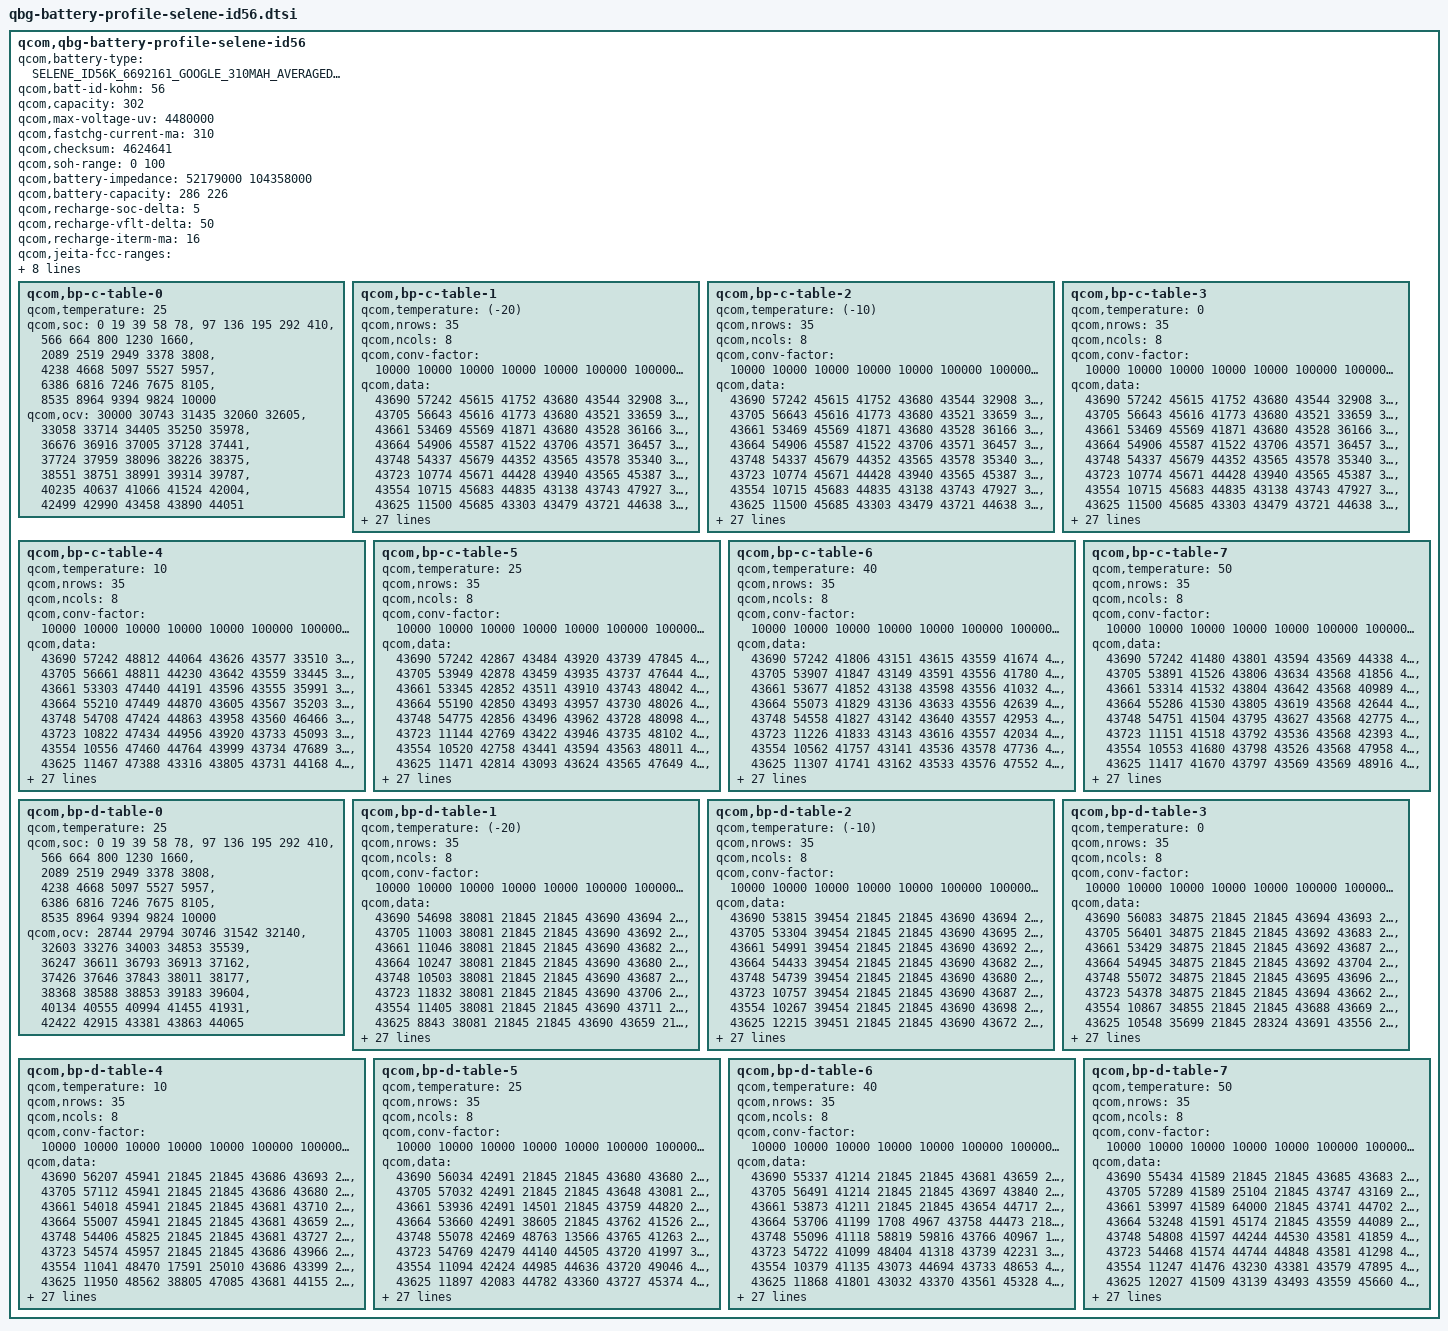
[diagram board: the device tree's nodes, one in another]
/*QBG Profiling Rev. 2.7*/

qcom,qbg-battery-profile-selene-id56 {
	qcom,battery-type = "SELENE_ID56K_6692161_GOOGLE_310MAH_AVERAGED_MASTERSLAVE_JUL3RD2023";
	qcom,batt-id-kohm = <56>;
	qcom,capacity = <302>;
	qcom,max-voltage-uv = <4480000>;
	qcom,fastchg-current-ma = <310>;
	qcom,checksum = <4624641>; /*@5, 0.005V, 4% */
	qcom,soh-range = <0 100>;
	/*Nominal_Impedance in 10nohm @ SOC 50% 25C* 0:fresh cell, 1: aged cell*/
	qcom,battery-impedance = <52179000 104358000>;
	/*Nominal_Capacity in mAh. 0: fresh cell, 1:aged cell*/ 
	qcom,battery-capacity = <286 226>;
	/*SOC delta (in percent) dropped from EOC SOC to enable recharge*/ 
	qcom,recharge-soc-delta =<5>;
	/*vfloat delta (in mV) dropped from regular vfloat in recharge*/ 
	qcom,recharge-vflt-delta =<50>;
	/*termination current (in mA) in recharge*/ 
	qcom,recharge-iterm-ma = <16>;

	qcom,jeita-fcc-ranges = <0  100 125000
				100 150 175000
				150 250 450000
				250 410 500000
				410 450 125000>;

	qcom,jeita-fv-ranges = <0   100 4480000
				100 150 4480000
				150 250 4480000
				250 410 4480000
				410 450 4480000>;

	/* COOL = 10 DegC, WARM = 41 DegC */
	qcom,jeita-soft-thresholds = <0x2b8a 0x14de>;
	/* COLD = 0 DegC, HOT = 45 DegC */
	qcom,jeita-hard-thresholds = <0x3257 0x128c>;
	/* COOL = 12 DegC, WARM = 39 DegC*/
	qcom,jeita-soft-hys-thresholds = <0x2a0b 0x161b>;
	qcom,jeita-soft-fcc-ua = <125000 125000>;
	qcom,jeita-soft-fv-uv = <4480000 4480000>;

	qcom,bp-c-table-0 {
		qcom,temperature = <25>;
		qcom,soc = <    0    19    39    58    78>,
			<   97   136   195   292   410>,
			<  566   664   800  1230  1660>,
			< 2089  2519  2949  3378  3808>,
			< 4238  4668  5097  5527  5957>,
			< 6386  6816  7246  7675  8105>,
			< 8535  8964  9394  9824 10000>;
		qcom,ocv = <30000 30743 31435 32060 32605>,
			<33058 33714 34405 35250 35978>,
			<36676 36916 37005 37128 37441>,
			<37724 37959 38096 38226 38375>,
			<38551 38751 38991 39314 39787>,
			<40235 40637 41066 41524 42004>,
			<42499 42990 43458 43890 44051>;
	};
	qcom,bp-c-table-1 {
		qcom,temperature = <(-20)>;
		qcom,nrows = <35>;
		qcom,ncols = <8>;
		qcom,conv-factor = <10000 10000 10000 10000 10000 100000 100000 10000>;
		qcom,data = <43690 57242 45615 41752 43680 43544 32908 39503>,
			<43705 56643 45616 41773 43680 43521 33659 39644>,
			<43661 53469 45569 41871 43680 43528 36166 39593>,
			<43664 54906 45587 41522 43706 43571 36457 34087>,
			<43748 54337 45679 44352 43565 43578 35340 34237>,
			<43723 10774 45671 44428 43940 43565 45387 33803>,
			<43554 10715 45683 44835 43138 43743 47927 34666>,
			<43625 11500 45685 43303 43479 43721 44638 34319>,
			<43918  9017 45691 43099 43285 43721 43843 33037>,
			<43824  9923 45676 43141 44687 43712 43832 32866>,
			<43164  9654 45611 43326 43047 43734 43281 33003>,
			<43058 15079 45577 43834 44702 43559 43997 33550>,
			<43402 14949 45787 43981 44598 43556 43966 33759>,
			<44644 15356 45783 44571 43999 43571 42178 33570>,
			<44246 14580 45768 44403 43868 43729 48642 33091>,
			<41603 14629 45742 41524 43238 43740 49067 34467>,
			<41853 16089 48481 41917 43056 43742 48682 34477>,
			<41263 16293 48394 41938 43078 43736 47530 34491>,
			<42904 16324 48445 41750 43402 43739 47534 34536>,
			<42058 16229 48426 41820 43514 43738 47544 34346>,
			<47652 15505 48607 41112 43476 43738 47399 34405>,
			<47254 15376 48605 41177 43319 43738 48943 34696>,
			<47427 15857 48421 40989 43273 43738 46055 34807>,
			<48957 13041 48445 41039 43507 43716 48495 34815>,
			<48623 13110 48415 41404 43416 43712 47171 34618>,
			<45656 12377 45708 41460 43490 43726 42507 33818>,
			<45066 14062 45669 41295 43288 43765 41829 39637>,
			<46820 14089 46057 42704 44677 43761 41609 38968>,
			<46929 13747 45946 42585 44663 43762 44036 40538>,
			<46339  2569 45117 42983 44875 43773 45030 40193>,
			<35837  2198 45471 42781 44421 43773 44754 36941>,
			<35246  2381 45377 42835 41892 43762 43295 38014>,
			<36376  3851 46609 42133 42666 43761 43451 61175>,
			<36042  3530 47059 42029 42068 43764 43033 58214>,
			<36282   699 46887 43003 41126 43760 44705 61409>;
	};
	qcom,bp-c-table-2 {
		qcom,temperature = <(-10)>;
		qcom,nrows = <35>;
		qcom,ncols = <8>;
		qcom,conv-factor = <10000 10000 10000 10000 10000 100000 100000 10000>;
		qcom,data = <43690 57242 45615 41752 43680 43544 32908 39503>,
			<43705 56643 45616 41773 43680 43521 33659 39644>,
			<43661 53469 45569 41871 43680 43528 36166 39593>,
			<43664 54906 45587 41522 43706 43571 36457 34087>,
			<43748 54337 45679 44352 43565 43578 35340 34237>,
			<43723 10774 45671 44428 43940 43565 45387 33803>,
			<43554 10715 45683 44835 43138 43743 47927 34666>,
			<43625 11500 45685 43303 43479 43721 44638 34319>,
			<43918  9017 45691 43099 43285 43721 43843 33037>,
			<43824  9923 45676 43141 44687 43712 43832 32866>,
			<43164  9654 45611 43326 43047 43734 43281 33003>,
			<43058 15079 45577 43834 44702 43559 43997 33550>,
			<43402 14949 45787 43981 44598 43556 43966 33759>,
			<44644 15356 45783 44571 43999 43571 42178 33570>,
			<44246 14580 45768 44403 43868 43729 48642 33091>,
			<41603 14629 45742 41524 43238 43740 49067 34467>,
			<41853 16089 48481 41917 43056 43742 48682 34477>,
			<41263 16293 48394 41938 43078 43736 47530 34491>,
			<42904 16324 48445 41750 43402 43739 47534 34536>,
			<42058 16229 48426 41820 43514 43738 47544 34346>,
			<47652 15505 48607 41112 43476 43738 47399 34405>,
			<47254 15376 48605 41177 43319 43738 48943 34696>,
			<47427 15857 48421 40989 43273 43738 46055 34807>,
			<48957 13041 48445 41039 43507 43716 48495 34815>,
			<48623 13110 48415 41404 43416 43712 47171 34618>,
			<45656 12377 45708 41460 43490 43726 42507 33818>,
			<45066 14062 45669 41295 43288 43765 41829 39637>,
			<46820 14089 46057 42704 44677 43761 41609 38968>,
			<46929 13747 45946 42585 44663 43762 44036 40538>,
			<46339  2569 45117 42983 44875 43773 45030 40193>,
			<35837  2198 45471 42781 44421 43773 44754 36941>,
			<35246  2381 45377 42835 41892 43762 43295 38014>,
			<36376  3851 46609 42133 42666 43761 43451 61175>,
			<36042  3530 47059 42029 42068 43764 43033 58214>,
			<36282   699 46887 43003 41126 43760 44705 61409>;
	};
	qcom,bp-c-table-3 {
		qcom,temperature = <0>;
		qcom,nrows = <35>;
		qcom,ncols = <8>;
		qcom,conv-factor = <10000 10000 10000 10000 10000 100000 100000 10000>;
		qcom,data = <43690 57242 45615 41752 43680 43544 32908 39503>,
			<43705 56643 45616 41773 43680 43521 33659 39644>,
			<43661 53469 45569 41871 43680 43528 36166 39593>,
			<43664 54906 45587 41522 43706 43571 36457 34087>,
			<43748 54337 45679 44352 43565 43578 35340 34237>,
			<43723 10774 45671 44428 43940 43565 45387 33803>,
			<43554 10715 45683 44835 43138 43743 47927 34666>,
			<43625 11500 45685 43303 43479 43721 44638 34319>,
			<43918  9017 45691 43099 43285 43721 43843 33037>,
			<43824  9923 45676 43141 44687 43712 43832 32866>,
			<43164  9654 45611 43326 43047 43734 43281 33003>,
			<43058 15079 45577 43834 44702 43559 43997 33550>,
			<43402 14949 45787 43981 44598 43556 43966 33759>,
			<44644 15356 45783 44571 43999 43571 42178 33570>,
			<44246 14580 45768 44403 43868 43729 48642 33091>,
			<41603 14629 45742 41524 43238 43740 49067 34467>,
			<41853 16089 48481 41917 43056 43742 48682 34477>,
			<41263 16293 48394 41938 43078 43736 47530 34491>,
			<42904 16324 48445 41750 43402 43739 47534 34536>,
			<42058 16229 48426 41820 43514 43738 47544 34346>,
			<47652 15505 48607 41112 43476 43738 47399 34405>,
			<47254 15376 48605 41177 43319 43738 48943 34696>,
			<47427 15857 48421 40989 43273 43738 46055 34807>,
			<48957 13041 48445 41039 43507 43716 48495 34815>,
			<48623 13110 48415 41404 43416 43712 47171 34618>,
			<45656 12377 45708 41460 43490 43726 42507 33818>,
			<45066 14062 45669 41295 43288 43765 41829 39637>,
			<46820 14089 46057 42704 44677 43761 41609 38968>,
			<46929 13747 45946 42585 44663 43762 44036 40538>,
			<46339  2569 45117 42983 44875 43773 45030 40193>,
			<35837  2198 45471 42781 44421 43773 44754 36941>,
			<35246  2381 45377 42835 41892 43762 43295 38014>,
			<36376  3851 46609 42133 42666 43761 43451 61175>,
			<36042  3530 47059 42029 42068 43764 43033 58214>,
			<36282   699 46887 43003 41126 43760 44705 61409>;
	};
	qcom,bp-c-table-4 {
		qcom,temperature = <10>;
		qcom,nrows = <35>;
		qcom,ncols = <8>;
		qcom,conv-factor = <10000 10000 10000 10000 10000 100000 100000 10000>;
		qcom,data = <43690 57242 48812 44064 43626 43577 33510 35317>,
			<43705 56661 48811 44230 43642 43559 33445 35247>,
			<43661 53303 47440 44191 43596 43555 35991 34825>,
			<43664 55210 47449 44870 43605 43567 35203 34961>,
			<43748 54708 47424 44863 43958 43560 46466 35706>,
			<43723 10822 47434 44956 43920 43733 45093 35790>,
			<43554 10556 47460 44764 43999 43734 47689 35388>,
			<43625 11467 47388 43316 43805 43731 44168 46347>,
			<43918  8987 47371 43507 43901 43732 44771 46173>,
			<43824  9772 47573 43410 43797 43565 44585 46308>,
			<43164  9617 47568 43409 43829 43557 44933 46956>,
			<43058 15079 47590 43045 43871 43581 43433 47085>,
			<43402 14877 47501 43180 43010 43571 43172 47030>,
			<44644 15238 47500 44674 43910 43557 48087 47063>,
			<44246 14589 47220 44198 43876 43741 47149 46495>,
			<41603 14815 47161 44250 43240 43743 47569 46531>,
			<41853 16078 47358 44063 43263 43742 47218 46574>,
			<41263 15966 47238 44096 43224 43742 47274 46487>,
			<42904 16369 47270 44448 43017 43742 47698 46587>,
			<42058 16229 47940 44465 43108 43737 42417 46580>,
			<47652 15600 47938 44440 43430 43739 42840 46347>,
			<47254 15453 47986 44543 43517 43739 42006 46400>,
			<47427 15616 47973 44346 43311 43739 47155 35477>,
			<48957 12803 47997 44395 43483 43736 48444 35552>,
			<48623 12529 47966 44307 43054 43737 48605 46493>,
			<45656 14003 47892 44529 43237 43716 42678 46117>,
			<45066 14135 47876 44500 43208 43713 41811 46186>,
			<46820 13749 47891 44380 43063 43725 41593 46376>,
			<46929  2578 47945 41481 43438 43721 44344 35423>,
			<46339  2240 47357 41878 43272 43723 44069 34943>,
			<35837  3737 47229 41753 44593 43722 45048 36794>,
			<35246  3232 47605 41089 44886 43723 44749 36215>,
			<36376  3403 47472 41182 41671 43721 43313 33111>,
			<36042   771 48842 41203 41204 43724 43418 33870>,
			<36282   242 48747 41928 41149 43725 43462 33836>;
	};
	qcom,bp-c-table-5 {
		qcom,temperature = <25>;
		qcom,nrows = <35>;
		qcom,ncols = <8>;
		qcom,conv-factor = <10000 10000 10000 10000 10000 100000 100000 10000>;
		qcom,data = <43690 57242 42867 43484 43920 43739 47845 48724>,
			<43705 53949 42878 43459 43935 43737 47644 48762>,
			<43661 53345 42852 43511 43910 43743 48042 48650>,
			<43664 55190 42850 43493 43957 43730 48026 48836>,
			<43748 54775 42856 43496 43962 43728 48098 48790>,
			<43723 11144 42769 43422 43946 43735 48102 48806>,
			<43554 10520 42758 43441 43594 43563 48011 47386>,
			<43625 11471 42814 43093 43624 43565 47649 47597>,
			<43918  8984 42953 43073 43624 43553 42196 47193>,
			<43824  9760 42980 43020 43638 43577 41780 47163>,
			<43164  9710 42900 43204 43590 43568 41485 47338>,
			<43058 15006 42886 43207 43543 43570 42566 47961>,
			<43402 14887 42932 43049 43574 43580 48046 47997>,
			<44644 15266 42923 43094 44009 43552 42645 47217>,
			<44246 14571 42599 43486 43805 43733 41431 47403>,
			<41603 14838 42507 43314 43871 43732 42689 47365>,
			<41853 16109 42716 43370 43898 43729 42401 47573>,
			<41263 15994 42749 43337 43899 43728 42049 47571>,
			<42904 16376 42652 43332 43846 43728 42615 47403>,
			<42058 16205 42673 43386 43238 43728 41569 47370>,
			<47652 15421 42671 43273 43133 43731 44125 47478>,
			<47254 15861 41306 43267 43394 43730 44322 48768>,
			<47427 13029 41332 43334 43411 43741 40987 48845>,
			<48957 13112 41336 44736 43021 43567 49032 48791>,
			<48623 12737 41318 44681 43843 43729 42149 47595>,
			<45656 14209 41327 44713 43899 43742 41642 47190>,
			<45066 13335 41236 44711 43178 43736 44275 47506>,
			<46820  2752 41238 44774 43167 43716 44833 47390>,
			<46929  2206 41238 44605 43230 43718 44968 48866>,
			<46339  3774 41237 44974 43016 43717 44975 48705>,
			<35837  3241 41290 44825 43493 43716 44766 48340>,
			<35246  3396 42676 44215 44579 43717 43342 45761>,
			<36376   872 42703 44150 44992 43574 43331 45161>,
			<36042   472 42513 44480 44074 43598 44687 46665>,
			<36282  1721 42560 44804 41482 43735 43498 46979>;
	};
	qcom,bp-c-table-6 {
		qcom,temperature = <40>;
		qcom,nrows = <35>;
		qcom,ncols = <8>;
		qcom,conv-factor = <10000 10000 10000 10000 10000 100000 100000 10000>;
		qcom,data = <43690 57242 41806 43151 43615 43559 41674 42173>,
			<43705 53907 41847 43149 43591 43556 41780 42156>,
			<43661 53677 41852 43138 43598 43556 41032 42846>,
			<43664 55073 41829 43136 43633 43556 42639 42825>,
			<43748 54558 41827 43142 43640 43557 42953 42872>,
			<43723 11226 41833 43143 43616 43557 42034 42859>,
			<43554 10562 41757 43141 43536 43578 47736 42763>,
			<43625 11307 41741 43162 43533 43576 47552 42962>,
			<43918  8982 41787 43142 43581 43580 49002 42988>,
			<43824  9774 41770 43145 43567 43575 46049 42916>,
			<43164  9616 41947 43799 43538 43545 40970 42600>,
			<43058 14979 41920 43988 43526 43548 41842 42696>,
			<43402 15065 41930 43833 43578 43546 42339 42739>,
			<44644 14924 41983 43847 44021 43522 44420 42791>,
			<44246 14470 41962 43180 43789 43529 44127 42871>,
			<41603 14825 41863 43164 43880 43530 41862 42169>,
			<41853 16010 41904 43241 43828 43575 42587 42843>,
			<41263 15970 41890 43152 43969 43571 41216 42752>,
			<42904 16373 41566 43218 43994 43583 40963 42870>,
			<42058 15521 41547 43204 43902 43569 44100 42140>,
			<47652 15481 41594 43180 43037 43528 44779 42017>,
			<47254 15647 41579 43848 43406 43573 44782 42099>,
			<47427 12905 41500 43141 43454 43571 44510 42075>,
			<48957 12432 41476 43046 43155 43571 42651 42019>,
			<48623 13979 41472 43256 43994 43570 41676 42963>,
			<45656 14203 41487 43256 43984 43582 44177 42798>,
			<45066 13783 41481 43223 43828 43559 45021 42870>,
			<46820  3042 41480 43441 43970 43526 48836 42224>,
			<46929  2439 41481 44707 43643 43598 36145 42051>,
			<46339  4021 41474 43283 43793 43528 42401 42281>,
			<35837  3507 41499 43279 43060 43734 44753 47764>,
			<35246   596 41568 44991 43258 43631 42637 47899>,
			<36376    19 41542 44580 44680 43570 44928 47551>,
			<36042  1740 41910 44585 44864 43607 43370 48732>,
			<36282  1983 41863 43471 45038 43583 43284 47536>;
	};
	qcom,bp-c-table-7 {
		qcom,temperature = <50>;
		qcom,nrows = <35>;
		qcom,ncols = <8>;
		qcom,conv-factor = <10000 10000 10000 10000 10000 100000 100000 10000>;
		qcom,data = <43690 57242 41480 43801 43594 43569 44338 41309>,
			<43705 53891 41526 43806 43634 43568 41856 41310>,
			<43661 53314 41532 43804 43642 43568 40989 41285>,
			<43664 55286 41530 43805 43619 43568 42644 41283>,
			<43748 54751 41504 43795 43627 43568 42775 41288>,
			<43723 11151 41518 43792 43536 43568 42393 41329>,
			<43554 10553 41680 43798 43526 43568 47958 41312>,
			<43625 11417 41670 43797 43569 43569 48916 41243>,
			<43918  9176 41713 43796 43554 43573 45475 41257>,
			<43824  9963 41697 43805 43735 43532 45339 41456>,
			<43164  9310 41621 43826 43563 43548 47122 41353>,
			<43058  9567 41617 43913 43553 43643 42646 40968>,
			<43402 15083 41631 43955 43579 43620 41456 41013>,
			<44644 14875 41601 43989 44028 43541 44913 41330>,
			<44246 15192 41610 43779 43975 43536 44442 42681>,
			<41603 14779 41657 43776 43828 43540 44498 42652>,
			<41853 14683 41634 43791 43789 43542 41771 42649>,
			<41263 15901 44374 43827 44006 43549 41785 41312>,
			<42904 16375 44356 43903 44009 43522 41926 41302>,
			<42058 15546 44404 43192 43991 43526 44512 42694>,
			<47652 15433 44408 43832 43207 43626 43390 42593>,
			<47254 15736 44386 44022 43101 43626 43323 42912>,
			<47427 12893 44394 43816 43122 43551 44166 42927>,
			<48957 12322 44304 43874 43865 43547 41916 42718>,
			<48623 14042 44316 43882 43921 43546 41683 41218>,
			<45656 13501 44313 43801 44003 43521 44857 41220>,
			<45066 13669 44314 43900 43991 43528 44559 42680>,
			<46820  2825 44315 43190 43788 43571 44547 42533>,
			<46929  2341 44293 43229 43886 43579 44973 42943>,
			<46339  3878 44313 43027 43865 43559 44980 42810>,
			<35837  3375 44304 43479 43797 43550 41432 42218>,
			<35246   974 44399 44710 43900 43636 42208 42395>,
			<36376   437 44406 43353 43397 43646 44208 47848>,
			<36042  1638 44373 43029 43349 43574 44687 42312>,
			<36282  1829 41636 43246 43078 43574 44584 42238>;
	};
	qcom,bp-d-table-0 {
		qcom,temperature = <25>;
		qcom,soc = <    0    19    39    58    78>,
			<   97   136   195   292   410>,
			<  566   664   800  1230  1660>,
			< 2089  2519  2949  3378  3808>,
			< 4238  4668  5097  5527  5957>,
			< 6386  6816  7246  7675  8105>,
			< 8535  8964  9394  9824 10000>;
		qcom,ocv = <28744 29794 30746 31542 32140>,
			<32603 33276 34003 34853 35539>,
			<36247 36611 36793 36913 37162>,
			<37426 37646 37843 38011 38177>,
			<38368 38588 38853 39183 39604>,
			<40134 40555 40994 41455 41931>,
			<42422 42915 43381 43863 44065>;
	};
	qcom,bp-d-table-1 {
		qcom,temperature = <(-20)>;
		qcom,nrows = <35>;
		qcom,ncols = <8>;
		qcom,conv-factor = <10000 10000 10000 10000 10000 100000 100000 10000>;
		qcom,data = <43690 54698 38081 21845 21845 43690 43694 21845>,
			<43705 11003 38081 21845 21845 43690 43692 21845>,
			<43661 11046 38081 21845 21845 43690 43682 21845>,
			<43664 10247 38081 21845 21845 43690 43680 21845>,
			<43748 10503 38081 21845 21845 43690 43687 21845>,
			<43723 11832 38081 21845 21845 43690 43706 21845>,
			<43554 11405 38081 21845 21845 43690 43711 21845>,
			<43625  8843 38081 21845 21845 43690 43659 21845>,
			<43918  8204 38029 21845   738 43690 43757 21845>,
			<43824  9765 38884 21845 62305 43690 43572 21845>,
			<43164 10066 36897 21845 38973 43690 44017 21845>,
			<43058  9253 36929 21845 40831 43690 43805 21845>,
			<43402  9615 36907 21845 40040 43690 43862 21845>,
			<44644 15088 40070 27296 36158 43691 43231 21845>,
			<44246 15241 40614 53636 46521 43691 43062 21845>,
			<41603 15209 39726 65395 48515 43688 43098 21845>,
			<41853 14577 34050 60216 47948 43688 43513 24106>,
			<41263 14430 33989 40658 42118 43689 43293 31035>,
			<42904 14649 34796 33235 41260 43694 44710  4410>,
			<42058 16023 34533 36736 41734 43694 44797   863>,
			<47652 15955 34556 35568 41720 43695 44651 12551>,
			<47254 16233 32777 46710 44345 43692 44660 15025>,
			<47427 15413 33565 45205 44131 43693 45027 11317>,
			<48957 15676 33772 45769 44883 43682 44270 54305>,
			<48623 12822 33376 48551 45018 43683 41624 56589>,
			<45656 12418 33451 48294 45027 43680 41074 55422>,
			<45066 12668 33501 49106 44165 43681 41250 56114>,
			<46820 14179 33410 48904 44421 43686 42499 55454>,
			<46929 13642 36160 48965 41628 43687 42616 55784>,
			<46339  2898 36213 48352 41917 43684 41309 56974>,
			<35837  3768 33441 48166 41783 43685 41160 56929>,
			<35246  3298 36170 48239 41839 43704 41781 57283>,
			<36376   571 33457 48213 41707 43704 41478 55634>,
			<36042   404 33283 48529 44873 43704 44343 56248>,
			<36282  1756 33372 48620 45043 43704 44417 50509>;
	};
	qcom,bp-d-table-2 {
		qcom,temperature = <(-10)>;
		qcom,nrows = <35>;
		qcom,ncols = <8>;
		qcom,conv-factor = <10000 10000 10000 10000 10000 100000 100000 10000>;
		qcom,data = <43690 53815 39454 21845 21845 43690 43694 21845>,
			<43705 53304 39454 21845 21845 43690 43695 21845>,
			<43661 54991 39454 21845 21845 43690 43692 21845>,
			<43664 54433 39454 21845 21845 43690 43682 21845>,
			<43748 54739 39454 21845 21845 43690 43680 21845>,
			<43723 10757 39454 21845 21845 43690 43687 21845>,
			<43554 10267 39454 21845 21845 43690 43698 21845>,
			<43625 12215 39451 21845 21845 43690 43672 21845>,
			<43918  8956 33800 21845 56244 43690 43567 21845>,
			<43824  8678 34402 21845 36576 43690 43906 21845>,
			<43164 10065 32919 14516 47317 43690 43416 21845>,
			<43058  9342 33340 63205 42188 43691 44748 21845>,
			<43402  9691 36144 63503 47284 43691 43389 21845>,
			<44644 14906 36496 33071 42859 43689 44715  4772>,
			<44246 15350 34969 46897 41772 43695 44639  8408>,
			<41603 15199 35358 48298 44086 43682 44873 56009>,
			<41853 14378 46452 48112 44623 43687 44111 52139>,
			<41263 14753 46371 41996 44709 43705 44497 62068>,
			<42904 14641 46536 42580 43288 43697 44347 65234>,
			<42058 16028 46554 41320 43307 43657 44446 64423>,
			<47652 15939 46554 41344 43078 43668 41971 58381>,
			<47254 16226 46421 41051 43134 43769 42699 59265>,
			<47427 15443 46425 41404 43448 43722 47342 59307>,
			<48957 13004 46383 41461 43375 43727 48663 59292>,
			<48623 13132 46564 41274 44581 43714 47946 59197>,
			<45656 12602 46580 41300 44946 43719 47658 58556>,
			<45066 14275 46440 42498 44876 43717 42367 58434>,
			<46820 13818 46392 42992 44236 43719 42197 58682>,
			<46929  3048 46382 42119 44060 43714 42995 64146>,
			<46339  2454 46559 42076 44145 43723 42695 64099>,
			<35837  3997 46495 42286 44111 43760 41409 64394>,
			<35246  3487 46464 42353 44152 43774 41202 64493>,
			<36376   907 46476 42240 44820 43751 41889 64145>,
			<36042   451 46464 42049 44686 43759 44324 58582>,
			<36282  1756 46490 42191 43385 43752 44096 58535>;
	};
	qcom,bp-d-table-3 {
		qcom,temperature = <0>;
		qcom,nrows = <35>;
		qcom,ncols = <8>;
		qcom,conv-factor = <10000 10000 10000 10000 10000 100000 100000 10000>;
		qcom,data = <43690 56083 34875 21845 21845 43694 43693 21845>,
			<43705 56401 34875 21845 21845 43692 43683 21845>,
			<43661 53429 34875 21845 21845 43692 43687 21845>,
			<43664 54945 34875 21845 21845 43692 43704 21845>,
			<43748 55072 34875 21845 21845 43695 43696 21845>,
			<43723 54378 34875 21845 21845 43694 43662 21845>,
			<43554 10867 34855 21845 21845 43688 43669 21845>,
			<43625 10548 35699 21845 28324 43691 43556 21845>,
			<43918 11660 35558 27905 32856 43690 43987 21845>,
			<43824  8437 46189 59040 42599 43691 43094 21845>,
			<43164 10043 47051 45353 44168 43688 44994 12377>,
			<43058  9342 46744 47570 44997 43689 44351 55130>,
			<43402  9504 45542 47338 44833 43695 44291 55472>,
			<44644 15055 45957 42870 43281 43684 41713 65033>,
			<44246 15287 46035 41131 43032 43658 41791 60649>,
			<41603 14469 45635 41911 43105 43751 48179 60302>,
			<41853 14762 45624 41473 43126 43721 45058 38717>,
			<41263 14800 45622 41617 43027 43725 48728 37104>,
			<42904 14659 45670 44364 43203 43714 48052 40288>,
			<42058 16087 45631 44309 43240 43713 47658 40099>,
			<47652 16357 45590 44410 43202 43716 47392 40955>,
			<47254 15586 45657 44407 43028 43739 47179 40537>,
			<47427 15819 45636 44378 43394 43737 47663 40558>,
			<48957 12800 45695 41600 43320 43740 41997 40557>,
			<48623 12446 45667 41502 44711 43730 42125 40940>,
			<45656 12624 45568 41932 44556 43740 42855 40113>,
			<45066 14146 45578 41094 45055 43736 42987 40374>,
			<46820 13669 45630 41085 44810 43713 42685 40288>,
			<46929  2822 45628 41467 44896 43721 41166 37528>,
			<46339  2362 45623 41220 44922 43766 41886 37587>,
			<35837  3883 45618 41299 44804 43762 41571 37382>,
			<35246  3545 45627 42639 45008 43772 41525 37484>,
			<36376   999 45768 41304 44594 43774 41499 37551>,
			<36042   448 45744 41411 43501 43771 41897 40047>,
			<36282  1783 45739 41354 43124 43770 41961 40145>;
	};
	qcom,bp-d-table-4 {
		qcom,temperature = <10>;
		qcom,nrows = <35>;
		qcom,ncols = <8>;
		qcom,conv-factor = <10000 10000 10000 10000 10000 100000 100000 10000>;
		qcom,data = <43690 56207 45941 21845 21845 43686 43693 21845>,
			<43705 57112 45941 21845 21845 43686 43680 21845>,
			<43661 54018 45941 21845 21845 43681 43710 21845>,
			<43664 55007 45941 21845 21845 43681 43659 21845>,
			<43748 54406 45825 21845 21845 43681 43727 21845>,
			<43723 54574 45957 21845 21845 43686 43966 21845>,
			<43554 11041 48470 17591 25010 43686 43399 21845>,
			<43625 11950 48562 38805 47085 43681 44155 25297>,
			<43918 11649 48299 48148 41611 43692 42496 56995>,
			<43824  8335 49078 41223 43514 43684 42093 64083>,
			<43164 10223 48695 44129 43258 43649 42728 37135>,
			<43058  9234 48833 44184 43037 43669 41329 40327>,
			<43402  9508 48678 44868 43036 43745 41445 39390>,
			<44644 15004 47371 44094 43153 43759 41734 34171>,
			<44246 15258 47566 44207 43142 43766 42460 32925>,
			<41603 14562 47519 44864 43028 43738 47247 36096>,
			<41853 14762 47497 44827 43124 43740 42368 36621>,
			<41263 14649 47493 44803 43010 43729 42455 36498>,
			<42904 16026 47488 44829 43040 43732 47689 35320>,
			<42058 15966 47517 44904 43015 43732 47685 34893>,
			<47652 16234 47499 44820 43113 43732 42182 35019>,
			<47254 15363 47522 44903 43111 43732 42537 34990>,
			<47427 15639 47197 44200 43120 43735 41329 35655>,
			<48957 13227 47194 44271 43092 43728 41257 35677>,
			<48623 12323 47195 44092 43518 43731 41460 35021>,
			<45656 14029 47171 44436 43391 43728 42998 35268>,
			<45066 13521 47217 41632 44759 43729 42197 36476>,
			<46820  2763 47214 41604 44660 43742 41335 36800>,
			<46929  2207 47123 41710 44619 43718 41472 36623>,
			<46339  3767 47127 41685 44554 43715 41643 36735>,
			<35837  3236 47205 41500 44774 43714 41640 36006>,
			<35246  3414 47211 41569 44716 43725 41483 35999>,
			<36376   878 47231 41685 43486 43726 41891 36730>,
			<36042   270 47535 44357 43020 43765 41977 36436>,
			<36282  1755 47543 44398 43258 43767 41976 36376>;
	};
	qcom,bp-d-table-5 {
		qcom,temperature = <25>;
		qcom,nrows = <35>;
		qcom,ncols = <8>;
		qcom,conv-factor = <10000 10000 10000 10000 10000 100000 100000 10000>;
		qcom,data = <43690 56034 42491 21845 21845 43680 43680 21845>,
			<43705 57032 42491 21845 21845 43648 43081 21845>,
			<43661 53936 42491 14501 21845 43759 44820 21845>,
			<43664 53660 42491 38605 21845 43762 41526 21845>,
			<43748 55078 42469 48763 13566 43765 41263 25022>,
			<43723 54769 42479 44140 44505 43720 41997 36424>,
			<43554 11094 42424 44985 44636 43720 49046 46175>,
			<43625 11897 42083 44782 43360 43727 45374 45386>,
			<43918  8847 41986 44713 43415 43719 46081 45252>,
			<43824  8313 42021 43381 43196 43739 46510 45672>,
			<43164 10045 42221 43516 44026 43740 42833 48339>,
			<43058  9641 42117 43265 43777 43728 42702 48555>,
			<43402  9491 42220 43387 43877 43729 41174 48533>,
			<44644 15003 42837 43272 43974 43713 41049 48370>,
			<44246 15232 42813 43509 43800 43731 41398 49131>,
			<41603 14488 42978 43489 43145 43735 41129 48715>,
			<41853 14756 42895 43507 43251 43560 41445 48767>,
			<41263 14713 42936 43299 43044 43567 42828 49064>,
			<42904 16081 42588 43456 43027 43560 41411 48753>,
			<42058 16267 42608 43468 43053 43561 41099 48858>,
			<47652 16202 42607 43473 43164 43561 41214 48807>,
			<47254 15382 42500 43484 43176 43563 41817 47372>,
			<47427 15727 42557 43478 43866 43732 41197 47399>,
			<48957 13221 42536 43264 43862 43732 41227 47366>,
			<48623 12318 42688 43343 43057 43563 42659 48836>,
			<45656 13932 42742 44788 43266 43554 42870 48982>,
			<45066 13505 42742 44686 43336 43731 41727 48991>,
			<46820  2696 42742 44700 43289 43741 44241 48974>,
			<46929  2885 42699 44764 43423 43728 44230 49003>,
			<46339  2401 42695 44653 43067 43735 44512 48955>,
			<35837  3868 42710 44970 43194 43732 41883 49101>,
			<35246  3337 42559 44668 43867 43741 41836 49131>,
			<36376   991 42502 44577 43893 43743 41099 48720>,
			<36042   509 42600 44680 43893 43740 41113 48690>,
			<36282  1675 42593 43357 43853 43731 41149 48837>;
	};
	qcom,bp-d-table-6 {
		qcom,temperature = <40>;
		qcom,nrows = <35>;
		qcom,ncols = <8>;
		qcom,conv-factor = <10000 10000 10000 10000 10000 100000 100000 10000>;
		qcom,data = <43690 55337 41214 21845 21845 43681 43659 21845>,
			<43705 56491 41214 21845 21845 43697 43840 21845>,
			<43661 53873 41211 21845 21845 43654 44717 21845>,
			<43664 53706 41199  1708  4967 43758 44473 21845>,
			<43748 55096 41118 58819 59816 43766 40967 12204>,
			<43723 54722 41099 48404 41318 43739 42231 35019>,
			<43554 10379 41135 43073 44694 43733 48653 47320>,
			<43625 11868 41801 43032 43370 43561 45328 47911>,
			<43918  8845 41832 43220 43473 43555 46385 47694>,
			<43824  8240 41743 43228 43237 43559 34945 42453>,
			<43164 10132 41764 43211 43947 43577 46423 42840>,
			<43058  9229 41775 43217 43602 43576 48694 42839>,
			<43402  9497 41774 43086 43911 43556 42951 41997>,
			<44644 14986 41927 43213 43590 43553 42761 42873>,
			<44246 14932 41967 43247 43957 43531 42587 42757>,
			<41603 14503 41861 43256 43995 43522 41425 42828>,
			<41853 14416 41867 43154 43889 43521 41158 42173>,
			<41263 14670 41916 43149 43229 43546 41555 41985>,
			<42904 15927 41890 43055 43233 43626 41736 42083>,
			<42058 16378 41565 43035 43862 43629 41470 42035>,
			<47652 15550 41538 43018 43883 43547 41467 42132>,
			<47254 15450 41590 43216 43816 43522 41345 42854>,
			<47427 15707 41592 43259 43975 43535 41381 42795>,
			<48957 13290 41571 43236 43817 43534 42667 42810>,
			<48623 12728 41492 43037 43261 43534 47950 42081>,
			<45656 13950 41501 43260 43462 43569 44313 42455>,
			<45066 13358 41497 43218 43514 43574 44892 42279>,
			<46820  2706 41502 43427 43047 43521 44108 42442>,
			<46929  2902 41500 43519 43875 43532 44370 42408>,
			<46339  2419 41494 43504 43982 43558 41565 41984>,
			<35837  3945 41570 43409 43916 43564 41388 42225>,
			<35246  3334 41583 43126 43952 43564 41256 42823>,
			<36376   989 41572 43046 43952 43557 41257 42802>,
			<36042   488 41589 43247 43958 43575 41408 42993>,
			<36282   343 41550 43137 43957 43530 41470 42976>;
	};
	qcom,bp-d-table-7 {
		qcom,temperature = <50>;
		qcom,nrows = <35>;
		qcom,ncols = <8>;
		qcom,conv-factor = <10000 10000 10000 10000 10000 100000 100000 10000>;
		qcom,data = <43690 55434 41589 21845 21845 43685 43683 21845>,
			<43705 57289 41589 25104 21845 43747 43169 21845>,
			<43661 53997 41589 64000 21845 43741 44702 21845>,
			<43664 53248 41591 45174 21845 43559 44089 21845>,
			<43748 54808 41597 44244 44530 43581 41859 45686>,
			<43723 54468 41574 44744 44848 43581 41298 48842>,
			<43554 11247 41476 43230 43381 43579 47895 47749>,
			<43625 12027 41509 43139 43493 43559 45660 42378>,
			<43918 11540 41688 43176 43443 43576 46549 42032>,
			<43824  8392 41715 43867 43013 43570 35251 42842>,
			<43164  9794 41707 43844 43907 43571 35609 42722>,
			<43058  9442 41620 43864 43541 43574 46014 41291>,
			<43402  9516 41616 43249 43958 43580 43005 42522>,
			<44644  9565 41608 43847 43544 43568 47256 41238>,
			<44246 14948 41639 43899 43598 43537 42351 41229>,
			<41603 15181 44373 43843 43928 43627 42987 41305>,
			<41853 14457 44383 43896 43996 43619 41450 42669>,
			<41263 14712 44356 43861 43865 43638 41805 42515>,
			<42904 15896 44364 43239 43189 43607 41154 42904>,
			<42058 16327 44406 43239 43863 43638 41840 42925>,
			<47652 15493 44408 43245 43786 43622 40993 42549>,
			<47254 15779 44384 43189 44001 43625 40980 42680>,
			<47427 12961 44395 43845 43904 43626 41425 41238>,
			<48957 13303 44306 43841 43923 43541 42842 41320>,
			<48623 12702 44315 43186 43233 43540 42172 42923>,
			<45656 13916 44288 43174 43435 43542 44315 42759>,
			<45066 13361 44290 43263 43016 43542 44085 42804>,
			<46820  2787 44290 43085 43796 43540 44359 42995>,
			<46929  2232 44291 43450 43955 43525 41438 42578>,
			<46339  2399 44295 43103 43638 43576 42088 42544>,
			<35837  3914 44315 43063 43628 43557 47868 42640>,
			<35246  3436 44317 43238 43625 43580 47630 41295>,
			<36376   804 44308 43183 43623 43535 42360 41268>,
			<36042   484 44386 43885 43592 43539 42126 41421>,
			<36282  1705 44390 43803 43584 43624 42784 41468>;
	};
};
